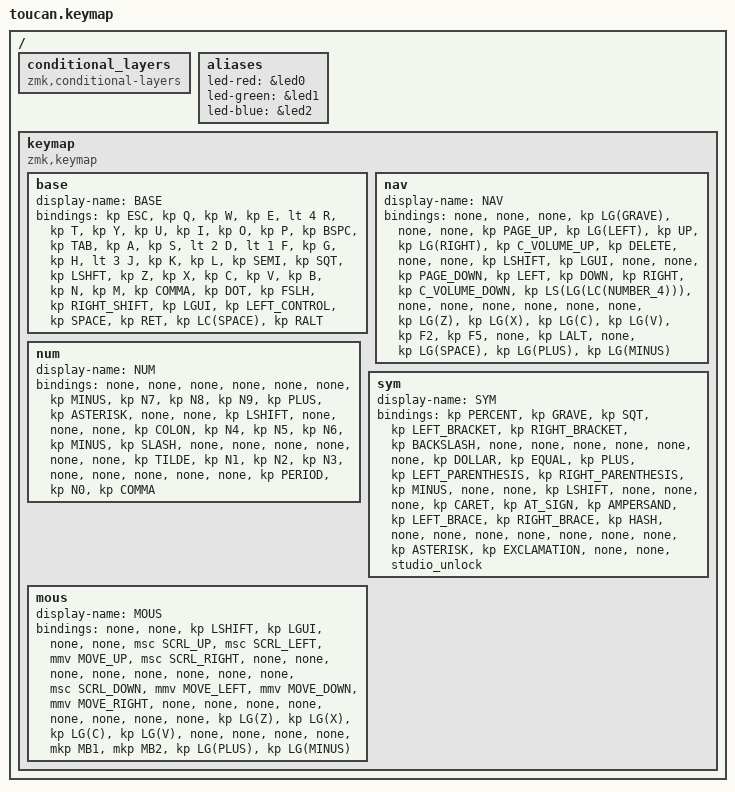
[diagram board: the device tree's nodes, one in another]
#include <dt-bindings/zmk/mouse.h>
#include <behaviors.dtsi>
#include <dt-bindings/zmk/keys.h>
#include <dt-bindings/zmk/pointing.h>

#define BASE 0
#define NAV  1
#define NUM  2
#define SYM  3
#define MOUS 4

/ {
    conditional_layers { compatible = "zmk,conditional-layers"; };

    aliases {
        led-red = &led0;
        led-green = &led1;
        led-blue = &led2;
    };

    keymap {
        compatible = "zmk,keymap";

        base {
            display-name = "BASE";
            bindings = <
&kp ESC  &kp Q  &kp W  &kp E  &lt 4 R  &kp T  &kp Y  &kp U  &kp I  &kp O  &kp P  &kp BSPC  &kp TAB  &kp A  &kp S  &lt 2 D  &lt 1 F  &kp G  &kp H  &lt 3 J  &kp K  &kp L  &kp SEMI  &kp SQT  &kp LSHFT  &kp Z  &kp X  &kp C  &kp V  &kp B  &kp N  &kp M  &kp COMMA  &kp DOT  &kp FSLH  &kp RIGHT_SHIFT  &kp LGUI  &kp LEFT_CONTROL  &kp SPACE  &kp RET  &kp LC(SPACE)  &kp RALT
            >;
        };

        nav {
            display-name = "NAV";
            bindings = <
&none  &none  &none  &kp LG(GRAVE)  &none  &none  &kp PAGE_UP  &kp LG(LEFT)  &kp UP  &kp LG(RIGHT)  &kp C_VOLUME_UP  &kp DELETE  &none  &none  &kp LSHIFT  &kp LGUI  &none  &none  &kp PAGE_DOWN  &kp LEFT  &kp DOWN  &kp RIGHT  &kp C_VOLUME_DOWN  &kp LS(LG(LC(NUMBER_4)))  &none  &none  &none  &none  &none  &none  &kp LG(Z)  &kp LG(X)  &kp LG(C)  &kp LG(V)  &kp F2  &kp F5  &none  &kp LALT  &none  &kp LG(SPACE)  &kp LG(PLUS)  &kp LG(MINUS)
            >;
        };

        num {
            display-name = "NUM";
            bindings = <
&none  &none  &none  &none  &none  &none  &kp MINUS  &kp N7  &kp N8  &kp N9  &kp PLUS  &kp ASTERISK  &none  &none  &kp LSHIFT  &none  &none  &none  &kp COLON  &kp N4  &kp N5  &kp N6  &kp MINUS  &kp SLASH  &none  &none  &none  &none  &none  &none  &kp TILDE  &kp N1  &kp N2  &kp N3  &none  &none  &none  &none  &none  &kp PERIOD  &kp N0  &kp COMMA
            >;
        };

        sym {
            display-name = "SYM";
            bindings = <
&kp PERCENT  &kp GRAVE  &kp SQT  &kp LEFT_BRACKET  &kp RIGHT_BRACKET  &kp BACKSLASH  &none  &none  &none  &none  &none  &none  &kp DOLLAR  &kp EQUAL  &kp PLUS  &kp LEFT_PARENTHESIS  &kp RIGHT_PARENTHESIS  &kp MINUS  &none  &none  &kp LSHIFT  &none  &none  &none  &kp CARET  &kp AT_SIGN  &kp AMPERSAND  &kp LEFT_BRACE  &kp RIGHT_BRACE  &kp HASH  &none  &none  &none  &none  &none  &none  &none  &kp ASTERISK  &kp EXCLAMATION  &none  &none  &studio_unlock
            >;
        };

        mous {
            display-name = "MOUS";
            bindings = <
&none  &none  &kp LSHIFT  &kp LGUI  &none  &none  &msc SCRL_UP  &msc SCRL_LEFT  &mmv MOVE_UP  &msc SCRL_RIGHT  &none  &none  &none  &none  &none  &none  &none  &none  &msc SCRL_DOWN  &mmv MOVE_LEFT  &mmv MOVE_DOWN  &mmv MOVE_RIGHT  &none  &none  &none  &none  &none  &none  &none  &none  &kp LG(Z)  &kp LG(X)  &kp LG(C)  &kp LG(V)  &none  &none  &none  &none  &mkp MB1  &mkp MB2  &kp LG(PLUS)  &kp LG(MINUS)
            >;
        };
    };
};
